# YTM32B1HA0 register map
Vendor: YTMicro; File version: 1.0
CPU: little endian, MPU, FPU, 2 interrupt priority bits
Registers are 32-bit, read-write, reset 0x0 unless marked. A register's access mark holds for its fields unless they carry their own. Offsets are from the block's base; [hi:lo] are bit positions; {n}, {i} and the like mark numbered series; 'fields as' and 'values as' point back to an identical list.

## FMU0 — Chip fault collect and process
Base 0x401C0000; register names take the prefix FMU0_
0x00 LOCK
  [15:0] KEY — Configure to unlock or lock protection.Write 0xA765 to this register to unlock;write 0x46B0 to lock. When read this register, it returns the lock status. ewline Read value 0x0 means lock state. ewline Read value 0x1 means unlock state. ewline
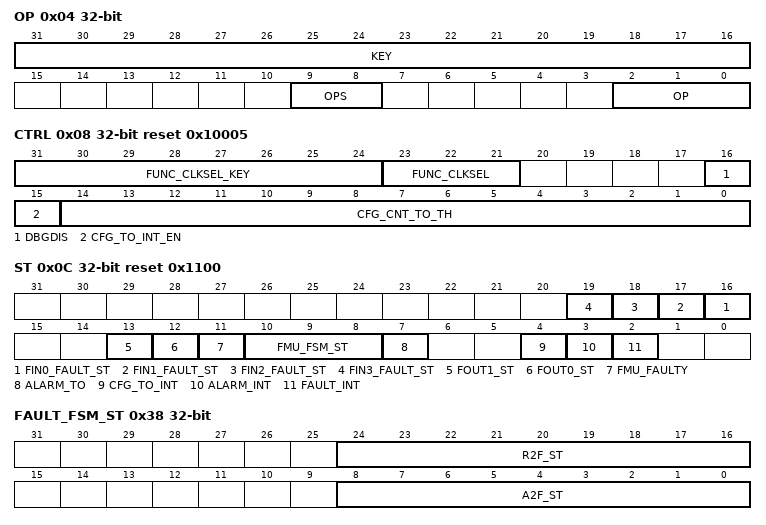
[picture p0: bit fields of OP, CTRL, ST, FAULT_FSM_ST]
0x04 OP
  [31:16] KEY wo — Write Only. OP can only be configured if KEY is written 0xFA65 at the same time.
  [9:8] OPS — Read Only. OPS indicates the operation status.
    0=IDLE; 1=In progress; 2=Aborted; 3=Successful
  [2:0] OP wo — Write only. Configure OP to change FMU status or clear status register.
    0=OP0, no operation; 1=OP1, put FMU in CFG state; 2=OP2, put FMU in RUN state; 3=OP3, clear FAULT_FSM_ST and ALARM_FSM_ST register; 4=OP4, set OPS to IDLE; others=others (Undefined)
0x08 CTRL reset 0x10005
  [31:24] FUNC_CLKSEL_KEY wo — Write only. FUNC_CLKSEL can be configured only if FUNC_CLKSEL_KEY is written 0x5A at the same time.
  [23:21] FUNC_CLKSEL — Select FMU module's functional clock source. This bit is reset by POR and should be configured when FMU module is static.
    0=SIRC_DIV4(SIRC clock divided by 4); 1=FIRC; 2=SXOSC; 3=FXOSC; 4=PLL; others=others (Reserved, no clock source selected)
  [16] DBGDIS — Configure to enable or disable fault input in debug mode. This bit is reset by POR.
    0=Fault input is enabled in debug mode; 1=Fault input is disabled in debug mode
  [15] CFG_TO_INT_EN — Configure this bit to enable CFG state timeout interrupt. This bit is reset by POR.
    0=CFG state timeout interrupt is disabled; 1=CFG state timeout interrupt is enabled
  [14:0] CFG_CNT_TO_TH — Configure the CFG state counter timeout threshold. The CFG state counter timeout if it reaches (CFG_CNT_TO_TH * 32). CFG_CNT_TO_TH is reset by POR.
0x0C ST reset 0x1100
  [n+16] FIN{n}_FAULT_ST (n=0..3) — FMU_ERR_IN{n} fault status. Write 1 to clear. This bit is reset by POR.
    0=No FMU_ERR_IN{n} fault; 1=FMU_ERR_IN{n} fault has occurred
  [13] FOUT1_ST ro — Read Only. FOUT1_ST monitors fault output 1. For test.
  [12] FOUT0_ST ro — Read Only. FOUT0_ST monitors fault output 0. For test.
  [11] FMU_FAULTY ro — Read Only. FMU_FAULTY indicates whether FMU FSM is FAULT state.
    0=FMU FSM is not in FAULT state; 1=FMU FSM is in FAULT state
  [10:8] FMU_FSM_ST ro — Read Only. Read FMU_FSM_ST to check FMU FSM current state.
    0=IDLE; 1=RUN; 2=CFG; 3=ALARM; 4=FAULT; others=others (Undefined)
  [7] ALARM_TO ro — Read Only. ALARM_TO indicates whether ALARM state timeout.
    0=ALARM state not timeout; 1=ALARM state timeout
  [4] CFG_TO_INT — CFG state timeout interrupt flag. Write 1 to clear.
    0=No CFG state timeout interrupt; 1=CFG state timeout interrupt has occurred
  [3] ALARM_INT — Alarm interrupt flag. Write 1 to clear.
    0=No alarm interrupt; 1=Alarm interrupt has occurred
  [2] FAULT_INT — Fault non maskable interrupt flag. Write 1 to clear.
    0=No fault non maskable interrupt; 1=Fault non maskable interrupt has occurred
0x10 CFG_CNT
  [19:0] CNT ro — Read Only. Read CFG_CNT returns the value of the CFG state counter.
0x14 FAULT_ST0
  [31:0] ST — ST[n](n=0~31) is the FAULT status of channel numbered by "n". Write 1 to clear. This bit is reset by POR. ewline When ST[n] is 0b, the channel[n] has no fault ewline When ST[n] is 1b, The channel[n] fault has occurred
0x18 FAULT_ST1
  [3:0] ST — ST[n](n=0~3) is the FAULT status of channel numbered by "n+32". Write 1 to clear. This bit is reset by POR. ewline When ST[n] is 0b, the channel[n+32] has no fault ewline When ST[n] is 1b, the channel[n+32] fault has occurred
0x34 FAULT_ST_KEY
  [31:0] KEY wo — Write Only. Write 0x52CB_6701 to unlock FAULT_ST write.
0x38 FAULT_FSM_ST
  [24:16] R2F_ST ro — Record the number of FAULT channel which caused FMU FSM turning to FAULT from RUN. Reset by POR. For internal test.
  [8:0] A2F_ST ro — Record the number of FAULT channel which caused FMU FSM turning to FAULT from ALARM. Reset by POR. For internal test.
0x3C ALARM_CNT_TO_TH reset 0x3A980
  [31:0] CNT_TO_TH — When ALARM counter threshold expired, ALARM timeout occurs
0x40 ALARM_CNT
  [31:0] CNT ro — Read Only. Read CNT returns the value of ALARM counter.
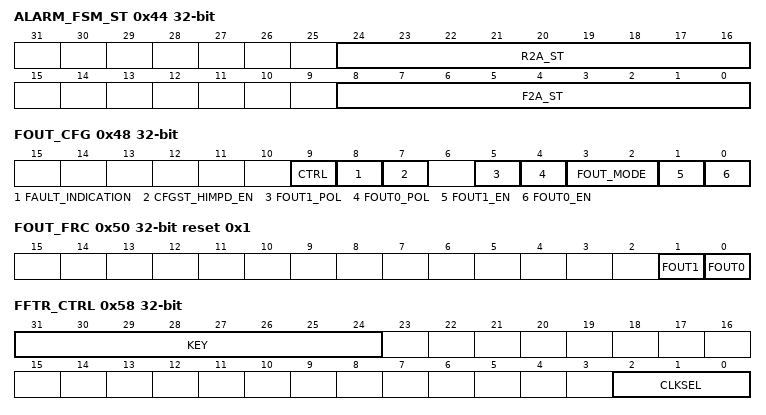
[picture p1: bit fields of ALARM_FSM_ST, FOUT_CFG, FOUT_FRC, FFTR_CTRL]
0x44 ALARM_FSM_ST
  [24:16] R2A_ST ro — Record the number of FAULT channel which caused FMU FSM turning to ALARM from RUN. Reset by POR. For internal test.
  [8:0] F2A_ST ro — Record the number of FAULT channel which caused FMU FSM turning to ALARM from FAULT. Reset by POR. For internal test.
0x48 FOUT_CFG
  [9] CTRL — Configure FMU_ERR_OUT source. It's reset by POR.
    0=FMU_ERR_OUT is controlled by FMU FSM; 1=FMU_ERR_OUT is controlled by Soft(FOUT_FRC)
  [8] FAULT_INDICATION — Configure FAULT_INDICATION to select whether FMU_ERR_OUT output as FAULT when in CFG state. It's reset by POR.
    0=FMU_ERR_OUT output as RUN state when in CFG state; 1=FMU_ERR_OUT output as FAULT state when in CFG state
  [7] CFGST_HIMPD_EN — Enable FMU_ERR_OUT high impedance output when FMU in CFG state. It's reset by POR.
    0=Disable high impedance output when in CFG state; 1=Enable high impedance output when in CFG state
  [5] FOUT1_POL — Configure FMU_ERR_OUT1 polarity. It's reset by POR.
    0=FMU_ERR_OUT1 is high when in fault state; 1=FMU_ERR_OUT1 is low when in fault state
  [4] FOUT0_POL — Configure FMU_ERR_OUT0 polarity. It's reset by POR.
    0=FMU_ERR_OUT0 is low when in fault state; 1=FMU_ERR_OUT0 is high when in fault state
  [3:2] FOUT_MODE — Select FMU fault output mode. It's reset by POR.
    0=Bi-stable mode; others=others (Undefined)
  [1] FOUT1_EN — Configure to enable output FMU_ERR_OUT1. It's reset by POR.
    0=FMU_ERR_OUT1 output disable; 1=FMU_ERR_OUT1 output enable
  [0] FOUT0_EN — Configure to enable output FMU_ERR_OUT0. It's reset by POR.
    0=FMU_ERR_OUT0 output disable; 1=FMU_ERR_OUT0 output enable
0x4C FOUT_MIN_WIN
  [21:0] MIN_WIN — Configure the minimum time window of FMU_ERR_OUT output. It's reset by POR. The minimum time is (MIN_WIN * 1024) cycles of functional clock.
0x50 FOUT_FRC reset 0x1
  [1] FOUT1 — Control FMU_ERR_OUT1 output
    0=FMU_ERR_OUT1 output low; 1=FMU_ERR_OUT1 output high
  [0] FOUT0 — Control FMU_ERR_OUT0 output
    0=FMU_ERR_OUT0 output low; 1=FMU_ERR_OUT0 output high
0x54 FOUT_CNT ro reset 0xFFFFFFFF
  [31:0] CNT — Read FOUT_CNT returns the value of FMU_ERR_OUT window counter
0x58 FFTR_CTRL
  [31:24] KEY wo — CLKSEL can only be configured if KEY is written 0xA5 at the same time.
  [2:0] CLKSEL — Select the clock source of FMU fail to react detect function. It's reset by POR and should be configured when FMU module is static.
    values as CTRL.FUNC_CLKSEL
0x5C FFTR_CNT_TO_TH
  [19:0] CNT_TO_TH — Configure FMU fail to react counter timeout threshold. The counter threshold is ((CNT_TO_TH + 1) * 4096) cycles of FFTR clock. It's reset by POR.
0x60 FFTR_CNT ro
  [31:0] CNT — Read FFTR_CNT returns the value of FMU fail to react counter
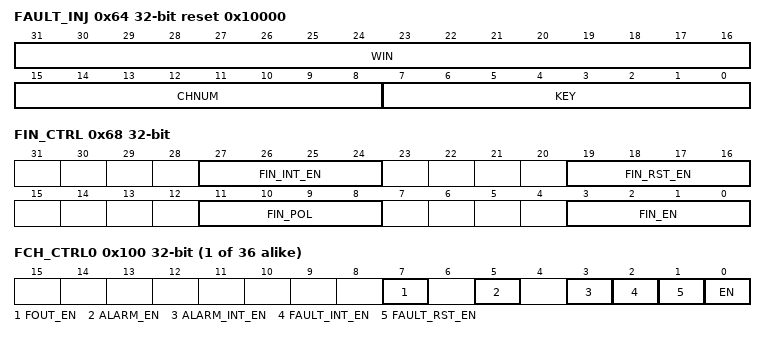
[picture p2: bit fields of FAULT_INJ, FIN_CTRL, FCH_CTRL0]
0x64 FAULT_INJ reset 0x10000
  [31:16] WIN — Configure fault injection time window
  [15:8] CHNUM — Configure the channel number to inject fault.
  [7:0] KEY wo — Fault injection assert when KEY is written 0x69.
0x68 FIN_CTRL
  [27:24] FIN_INT_EN — Enable FMU_ERR_IN fault to generate interrupt. FIN_INT_EN[n] enables the correspond FMU_ERR_INn to generate interrupt. FIN_INT_EN is reset by POR. ewline When FIN_INT_EN[n] is 0b, FMU_ERR_INn fault not generate interrupt. ewline When FIN_INT_EN[n] is 1b, FMU_ERR_INn fault generate interrupt.
  [19:16] FIN_RST_EN — Enable FMU_ERR_IN fault to generate reset. FIN_RST_EN[n] enables the correspond FMU_ERR_INn to generate reset. FIN_RST_EN is reset by POR. ewline When FIN_RST_EN[n] is 0b, FMU_ERR_INn fault not generate reset. ewline When FIN_RST_EN[n] is 1b, FMU_ERR_INn fault generate reset.
  [11:8] FIN_POL — Select FMU_ERR_IN Polarity. FIN_POL[n] select the polarity of the correspond FMU_ERR_INn. It's reset by POR. ewline When FIN_POL[n] is 0b, FMU_ERR_INn input high will generate fault. ewline When FIN_POL[n] is 1b, FMU_ERR_INn input low will generate fault.
  [3:0] FIN_EN — Enable FMU_ERR_IN input. Set FIN_EN[n] to 1, the correspond FMU_ERR_INn input is enabled. It's reset by POR. ewline When FIN_EN[n] is 0b, FMU_ERR_INn is disable. ewline When FIN_EN[n] is 1b, FMU_ERR_INn is enable.
{0x100+4i} FCH_CTRL{i} (i=0..35)
  [7] FOUT_EN — Enable FMU_ERR_OUT when the fault occurs. It's reset by POR.
    0=FMU_ERR_OUT disabled when the fault occurs; 1=FMU_ERR_OUT enabled when the fault occurs
  [5] ALARM_EN — Enable the FMU FSM enter ALARM state when the fault comes. It's reset by POR.
    0=The FMU FSM won't enter ALARM state when the fault comes; 1=The FMU FSM enter ALARM state when the fault comes
  [3] ALARM_INT_EN — Enable alarm to generate interrupt. It's reset by POR.
    0=The alarm not generate interrupt; 1=The alarm generates interrupt
  [2] FAULT_INT_EN — Enable fault to generate interrupt. It's reset by POR.
    0=The fault not generate interrupt; 1=The fault generates interrupt
  [1] FAULT_RST_EN — Enable fault to generate reset. It's reset by POR.
    0=The fault not generate reset; 1=The fault generate reset
  [0] EN — Enable the fault channel. It's reset by POR.
    0=The fault channel is disable; 1=The fault channel is enable
